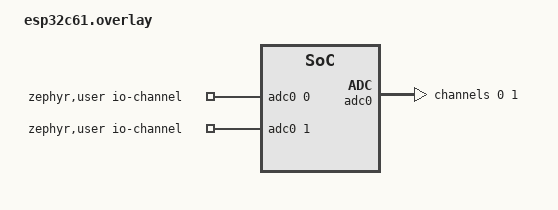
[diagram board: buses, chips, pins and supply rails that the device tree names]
/*
 * SPDX-License-Identifier: Apache-2.0
 *
 * Copyright (c) 2026 Espressif Systems (Shanghai) Co., Ltd.
 */

/ {
	zephyr,user {
		/* adjust channel number according to pinmux in board.dts */
		io-channels = <&adc0 0>, <&adc0 1>;
	};
};

&adc0 {
	#address-cells = <1>;
	#size-cells = <0>;
	status = "okay";

	channel@0 {
		reg = <0>;
		zephyr,gain = "ADC_GAIN_1_4";
		zephyr,reference = "ADC_REF_INTERNAL";
		zephyr,acquisition-time = <ADC_ACQ_TIME_DEFAULT>;
		zephyr,resolution = <12>;
	};

	channel@1 {
		reg = <1>;
		zephyr,gain = "ADC_GAIN_1_4";
		zephyr,reference = "ADC_REF_INTERNAL";
		zephyr,acquisition-time = <ADC_ACQ_TIME_DEFAULT>;
		zephyr,resolution = <12>;
	};
};
